# S1C31D50 register map
Vendor: Epson; Series: S1C31D50; File version: 1.00
ARM 32-bit Cortex-M0 plus Microcontroller based device, CPU clock up to 16MHz
CPU: CM0PLUS r0p1, little endian, MPU, no FPU, VTOR, 2 interrupt priority bits
Registers are 16-bit, read-write, reset 0x0 unless marked. A register's access mark holds for its fields unless they carry their own. Offsets are from the block's base; lines under a group give offsets from that group; [hi:lo] are bit positions; {n}, {i} and the like mark numbered series; 'fields as' and 'values as' point back to an identical list; <NAME> marks a mode.

## Memory map
0x00156700 HWPCOMMON size 0x54 — HW Processor Common Function
0x00156700 SOUNDPLAY size 0x54 — Sound Play Fucntion
0x00156700 MEMCHECK size 0x54 — Memory Check Function
0x00200000 SYS size 0x2 — System register
0x00200020 PWGA size 0x4 — Operation mode and voltage control
0x00200040 CLG size 0x1A — Clock sources control and clock supply management
0x00200080 CACHE size 0x10 — Cache controller
0x002000A0 WDT2 size 0x6 — Watchdog 2 timer counter, clock source and clock division ratio control
0x002000C0 RTCA size 0x14 — Real-time clock control
0x00200100 SVD3 size 0xA — Supply voltage detector control
0x00200160 T16_0 size 0xE — 16 Timer / Counter, counting up or down from different sources
0x002001B0 FLASHC size 0x2 — Flash controller
0x00200200 PPORT size 0xE4 — I/O P0-9,PA,PD Ports control
0x00200300 UPMUX size 0x20 — Universal port multiplexer control
0x00200380 UART3_0 size 0x16 — UART3 channel 0 control
0x002003A0 T16_1 size 0xE
0x002003B0 SPIA_0 size 0x10 — Synchronous serial interface control
0x002003C0 I2C_0 size 0x18 — I2C channel 0 control
0x00200400 T16B_0 size 0x40 — 16-bit PWM timer channel 0 comparator/capture control
0x00200440 T16B_1 size 0x40 — 16-bit PWM timer channel 1 comparator/capture control
0x00200480 T16_3 size 0xE
0x002004A0 T16_4 size 0xE
0x002004C0 T16_5 size 0xE
0x002004D0 SPIA_2 size 0x10 — Synchronous serial interface control
0x00200600 UART3_1 size 0x16 — UART3 channel 1 control
0x00200620 UART3_2 size 0x16 — UART3 channel 2 control
0x00200660 T16_6 size 0xE
0x00200670 SPIA_1 size 0x10 — Synchronous serial interface control
0x00200680 T16_2 size 0xE
0x00200690 QSPI_0 size 0x1A — Quad Synchronous Serial Interface channel 0
0x002006C0 I2C_1 size 0x18 — I2C channel 1 control
0x002006E0 I2C_2 size 0x18 — I2C channel 2 control
0x00200720 REMC3 size 0x14 — IR Remote Controller
0x00200780 T16_7 size 0xE
0x002007A0 ADC12A_0 size 0x1E — 12 bit ADC controller
0x00200840 RFC_0 size 0x20
0x00200860 SDAC_0 size 0xE — SOUND DAC
0x002008A0 HWPROC size 0xC — HW Processor
0x00201000 DMAC size 0x1018 — PrimeCell uDMA Controller

## Interrupts
0 DMAC
1 SVD3
2 PPORT_01 (PPORT)
3 PPORT_23 (PPORT)
4 PPORT_OTHER (PPORT)
5 CLG
6 RTC (RTCA)
7 HWPROC
8 SDAC_0
9 UART3_0
10 T16_1
11 SPIA_0
12 I2C_0
13 T16B_0
14 T16B_1
15 UART3_1
16 T16_2
17 QSPI_0
18 I2C_1
19 UART3_2_T16_0 (T16_0, UART3_2)
20 T16_3
21 SPIA_1
22 T16_4
23 T16_5
24 T16_6
25 RFC_0
26 ADC12A_0
27 SPIA_2_T16_7 (SPIA_2, T16_7)
28 I2C_2
29 REMC3

## ADC12A_0 — 12 bit ADC controller
Base 0x002007A0
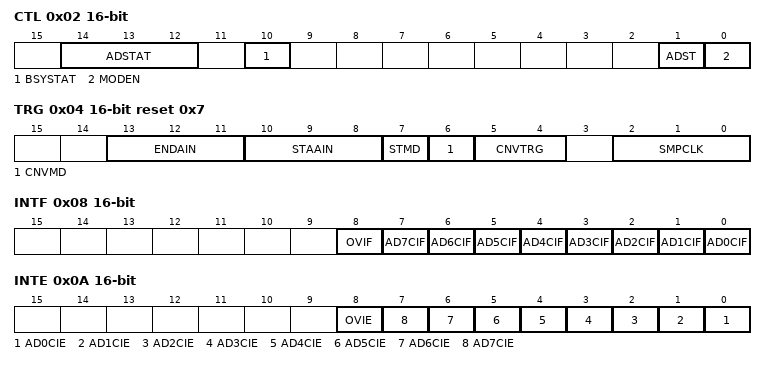
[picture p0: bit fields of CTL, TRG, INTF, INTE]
0x02 CTL — ADC Control Register
  [14:12] ADSTAT ro — ADC channel status
  [10] BSYSTAT ro — ADC busy status
    0=IDLE (ADC is Idle); 1=BUSY (ADC is Busy)
  [1] ADST — Conversion control
    0=STOP (Conversion control is stopped); 1=START (Conversion control is started/running)
  [0] MODEN — AD enable, ADCLK enable
    0=DISABLE (Disabled); 1=ENABLE (Enabled)
0x04 TRG reset 0x7 — A/D Converter Trigger/Channel select Register
  [13:11] ENDAIN — End channel select
  [10:8] STAAIN — Start channel select
  [7] STMD — Data store mode
  [6] CNVMD — Conversion store mode
    0=SINGLE; 1=CONTINUOUS
  [5:4] CNVTRG — Conversion trigger select
    0=SOFTWARE; 1=16BIT_TIMER; 3=ADTRG_PIN
  [2:0] SMPCLK — Sampling clock count
    {v}={v+4}CLK ({v+4} Clocks) (v=0..7)
0x06 CFG — ADC configuration register
  [1:0] VRANGE — Comparator input voltage range
    0=IQ (Conversion Disabled (IQ)); 1=4_8 (4.8 to 5.5V); 2=3_6 (3.6 to 5.5V); 3=1_8 (1.8 to 5.5V)
0x08 INTF — ADC interrupt flag register
  [8] OVIF write-1-clears — Overrun error interrupt flag
    0=NO_ERROR; 1=ERROR
  [n] AD{n}CIF write-1-clears (n=0..7) — Ch{n} conversion interrupt flag.
    0=NOT_COMPLETE (Conversion not complete); 1=COMPLETE (Conversion complete)
0x0A INTE — ADC interrupt enable
  [all] fields
    0=DISABLE (Disabled); 1=ENABLE (Enabled)
  [8] OVIE write-1-clears — Overrun interrupt enable
  [n] AD{n}CIE write-1-clears (n=0..7) — Ch{n} conversion interrupt enable
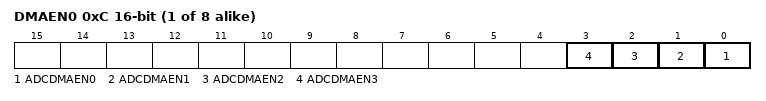
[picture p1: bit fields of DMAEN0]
{0xC+2i} DMAEN{i} (i=0..7) — DMA request enable
  [all] fields
    0=DISABLE (Disabled); 1=ENABLE (Enabled)
  [n] ADCDMAEN{n} (n=0..3) — DMA ch{n} enable
0x1C ADD ro — ADC Result Register
  [15:0] ADD — Conversion data

## Licence text in the file
Copyright (C) SEIKO EPSON CORPORATION 2017-2018. All rights reserved.
